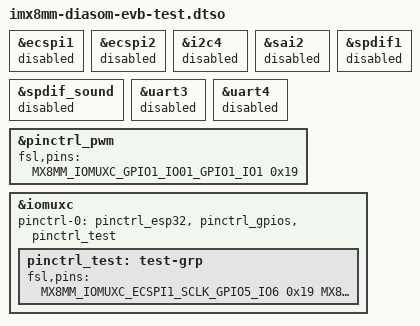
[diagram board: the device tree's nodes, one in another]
/* SPDX-License-Identifier: GPL-2.0+ */
/* SPDX-FileCopyrightText: Alexander Shiyan <shc_work@mail.ru> */

/dts-v1/;
/plugin/;

#include <arm64/freescale/imx8mm-pinfunc.h>

&ecspi1 {
	status = "disabled";
};

&ecspi2 {
	status = "disabled";
};

&i2c4 {
	status = "disabled";
};

&sai2 {
	status = "disabled";
};

&spdif_sound {
	status = "disabled";
};

&spdif1 {
	status = "disabled";
};

&uart3 {
	status = "disabled";
};

&uart4 {
	status = "disabled";
};

/*
 * GPIO Connections:
 * X8.1		(UART4_TXD GPIO5.29)	<=R1K=>	X8.2 (UART4_RXD GPIO5.28)
 * X9.1		(UART3_TXD GPIO5.27)	<=R1K=>	X9.2 (UART3_RXD GPIO5.26)
 * X13.7	(I2C4_SDA GPIO5.21)	<=R1K=>	X13.8 (I2C4_SCL GPIO5.20)
 * X13.10	(SAI2_RXFS GPIO4.21)	<=R1K=>	--> X13.8
 * X13.11	(SAI2_TXD GPIO4.26)	<=R1K=>	X13.12 (SAI2_MCLK GPIO4.27)
 * X13.13	(SAI2_TXC GPIO4.25)	<=R1K=>	X13.14 (SAI2_RXD GPIO4.23)
 * X13.15	(SAI2_RXC GPIO4.22)	<=R1K=>	X13.16 (SAI2_TXFS GPIO4.24)
 * X14.3	(GPIO1_IO0 GPIO1.0)	<=R1K=>	X14.4 (GPIO1_IO1 GPIO1.1)
 * X14.6	(GPIO1_IO4 GPIO1.4)	<=R1K=>	X14.7 (GPIO1_IO5 GPIO1.5)
 * X14.13	(GPIO1_IO11 GPIO1.11)	<=R1K=>	X14.15 (GPIO1_IO13 GPIO1.13)
 * X15.3	(SPDIF_CLK GPIO5.5)	<=R1K=>	X15.4 (SPDIF_TX GPIO5.3)
 * X15.5	(SPDIF_RX GPIO5.4)	<=R1K=>	--> X15.3
 * X15.9	(ESCPI2_SCLK GPIO5.10)	<=R1K=>	X15.10 (ESCPI2_MOSI GPIO5.11)
 * X15.11	(ESCPI2_MISO GPIO5.12)	<=R1K=>	X15.12 (ESCPI2_CS0 GPIO5.13)
 * X15.13	(ECSPI1_SCLK GPIO5.6)	<=R1K=>	X15.14 (ESCPI1_MOSI GPIO5.7)
 * X15.15	(ESCPI1_MISO GPIO5.8)	<=R1K=>	X15.16 (ESCPI1_CS0 GPIO5.9)
*/

&pinctrl_pwm {
	fsl,pins = <
		MX8MM_IOMUXC_GPIO1_IO01_GPIO1_IO1		0x19	/* PWM1_OUT */
	>;
};

&iomuxc {
	pinctrl-0 = <&pinctrl_esp32 &pinctrl_gpios &pinctrl_test>;

	pinctrl_test: test-grp {
		fsl,pins = <
			MX8MM_IOMUXC_ECSPI1_SCLK_GPIO5_IO6	0x19	/* ECSPI1_SCLK */
			MX8MM_IOMUXC_ECSPI1_MOSI_GPIO5_IO7	0x19	/* ESCPI1_MOSI */
			MX8MM_IOMUXC_ECSPI1_MISO_GPIO5_IO8	0x19	/* ESCPI1_MISO */
			MX8MM_IOMUXC_ECSPI1_SS0_GPIO5_IO9	0x19	/* ESCPI1_CS0 */
			MX8MM_IOMUXC_ECSPI2_SCLK_GPIO5_IO10	0x19	/* ESCPI2_SCLK */
			MX8MM_IOMUXC_ECSPI2_MOSI_GPIO5_IO11	0x19	/* ESCPI2_MOSI */
			MX8MM_IOMUXC_ECSPI2_MISO_GPIO5_IO12	0x19	/* ESCPI2_MISO */
			MX8MM_IOMUXC_ECSPI2_SS0_GPIO5_IO13	0x19	/* ESCPI2_CS0 */
			MX8MM_IOMUXC_I2C4_SCL_GPIO5_IO20	0x19	/* I2C4_SCL */
			MX8MM_IOMUXC_I2C4_SDA_GPIO5_IO21	0x19	/* I2C4_SDA */
			MX8MM_IOMUXC_SAI2_MCLK_GPIO4_IO27	0x19	/* SAI2_MCLK */
			MX8MM_IOMUXC_SAI2_RXC_GPIO4_IO22	0x19	/* SAI2_RXC */
			MX8MM_IOMUXC_SAI2_RXD0_GPIO4_IO23	0x19	/* SAI2_RXD */
			MX8MM_IOMUXC_SAI2_RXFS_GPIO4_IO21	0x19	/* SAI2_RXFS */
			MX8MM_IOMUXC_SAI2_TXC_GPIO4_IO25	0x19	/* SAI2_TXC */
			MX8MM_IOMUXC_SAI2_TXD0_GPIO4_IO26	0x19	/* SAI2_TXD */
			MX8MM_IOMUXC_SAI2_TXFS_GPIO4_IO24	0x19	/* SAI2_TXFS */
			MX8MM_IOMUXC_SPDIF_TX_GPIO5_IO3		0x19	/* SPDIF_TX */
			MX8MM_IOMUXC_SPDIF_RX_GPIO5_IO4		0x19	/* SPDIF_RX */
			MX8MM_IOMUXC_SPDIF_EXT_CLK_GPIO5_IO5	0x19	/* SPDIF_CLK */
			MX8MM_IOMUXC_UART3_RXD_GPIO5_IO26	0x19	/* UART3_RXD */
			MX8MM_IOMUXC_UART3_TXD_GPIO5_IO27	0x19	/* UART3_TXD */
			MX8MM_IOMUXC_UART4_RXD_GPIO5_IO28	0x19	/* UART4_RXD */
			MX8MM_IOMUXC_UART4_TXD_GPIO5_IO29	0x19	/* UART4_TXD */
		>;
	};
};
